# IOMUX_1.0 register map
Vendor: Texas Instruments
Peripheral module from a debugger description file (folder mspm33c321x).
Registers are 32-bit, read-write, no defined reset value unless marked. A register's access mark holds for its fields unless they carry their own. Offsets are as the file gives them; lines under a group give offsets from that group; [hi:lo] are bit positions; {n}, {i} and the like mark numbered series; 'fields as' and 'values as' point back to an identical list; <NAME> marks a mode.

## IOMUX
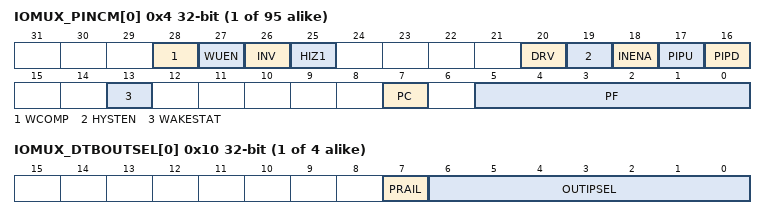
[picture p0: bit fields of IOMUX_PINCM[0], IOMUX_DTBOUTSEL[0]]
{0x4+4i} IOMUX_PINCM[{i}] (i=0..94) access per field — Pin Control Management Register in SECCFG region
  [28] WCOMP rw — Wakeup Compare Value bit
    0=MATCH0 (Wakeup on a match of 0); 1=MATCH1 (Wakeup on a match of 1)
  [27] WUEN rw — Wakeup Enable bit
    0=DISABLE (wakeup is disabled.); 1=ENABLE (wakeup is enabled)
  [26] INV rw — Data inversion selection
    0=DISABLE (Data inversion is disabled.); 1=ENABLE (Data inversion is enabled)
  [25] HIZ1 rw — High output value will tri-state the output when this bit is enabled
    0=DISABLE (open-drain is disabled.); 1=ENABLE (open-drain is enabled.)
  [20] DRV rw — Drive strength control selection, for HS IOCELL only
    0=DRVVAL0 (Drive setting of 0 selected); 1=DRVVAL1 (Drive setting of 1 selected)
  [19] HYSTEN rw — Hystersis Enable Control Selection
    0=DISABLE (hysteresis is disabled.); 1=ENABLE (hysteresis is enabled)
  [18] INENA rw — Input Enable Control Selection
    0=DISABLE (Input enable is disabled.); 1=ENABLE (Input enable is enabled.)
  [17] PIPU rw — Pull Up control selection
    0=DISABLE (Pull up is disabled.); 1=ENABLE (Pull up is enabled)
  [16] PIPD rw — Pull Down control selection
    0=DISABLE (Pull down is disabled.); 1=ENABLE (Pull down is enabled)
  [13] WAKESTAT ro — This has the IOPAD WAKEUP signal as status bit.
    0=DISABLE (wakeup source is NOT from this IOCELL); 1=ENABLE (wakeup source is from this IOCELL)
  [7] PC rw — Peripheral is Connected
    0=UNCONNECTED (The output of the peripheral (and its output enable) will not propagate to the IOCELL); 1=CONNECTED (The output latch of the dataflow will be transparent)
  [5:0] PF rw — P channel Function selection bits
    0=MINIMUM (Reserved as unconnected); 63=MAXIMUM (An encoding per function that can be connected to this pin.)
0x1900 IOMUX_LMGMT_DFT_ATRT group
  0x00 IOMUX_DTBENA — DTB ENA Register
    [31:0] ENABLE — DTB Enable
      0=DISABLE (Disable DTB output); 1=ENABLE (Enable DTB output)
  0x0C IOMUX_DTBBUSSEL — DTBBUSSEL Register
    [31:0] SEL — DTB bus selector
      0=MIN (DTB bus 0 is selected); 0xFFFFFFFF=MAX (dtb bus 0xffffffff is selected)
  {0x10+4j} IOMUX_DTBOUTSEL[{j}] (j=0..3) — DTBOUSEL Register
    [7] PRAIL — PRAIL bit to identify the Power Rail of the selected IP.
      0=SVTSEL (Selected IP is SVT); 1=ULLSEL (Selected IP is ULL)
    [6:0] OUTIPSEL — Select bits to configure the output IP for the selected DTB Lane.
      0=MINIMUM (Smallest value); 127=MAXIMUM (Highest possible value)
  {0x90+4j} IOMUX_DTBDIR[{j}] (j=0..3) — DTBDIR Register
    [5:0] DIR — DTB lane direction bit, 0: DTB OUTPUT enable, 1: DTB INPUT enable
      0=OUT (DTN lane direction is output, from core to PAD); 1=IN (DTN lane direction is input, from PAD to core)
